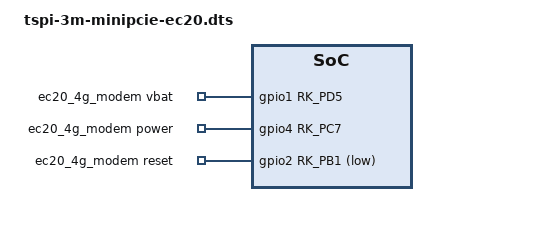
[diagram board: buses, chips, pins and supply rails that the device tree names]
/********************************************************************
 * SPDX-License-Identifier: (GPL-2.0+ OR MIT)
 *
 * Copyright (c) 2023 Rockchip Electronics Co., Ltd.
 * Copyright (c) 2026 LCKFB <lckfb@sz-jlc.com>
 *********************************************************************
 * Wiki (Chinese): https://wiki.lckfb.com/
 * Wiki (English): https://wiki.lckfb.com/en/
 *********************************************************************/

/*
 * Overlay: tspi-3m-minipcie-ec20.dtbo
 *
 * Purpose:
 *   Configures the MINI-PCIe slot for Quectel EC20 4G LTE modem.
 *   Registers the modem platform device and its GPIO pinmux.
 *   SATA0 and PCIe0 are not used in this mode and remain disabled
 *   (their default state in rk3576.dtsi).
 *
 * Hardware:
 *   - EC20 power supply (VBAT): GPIO1_D5 (active-high)
 *   - EC20 power enable:        GPIO4_C7 (active-high)
 *   - EC20 reset:               GPIO2_B1 (active-low)
 *
 * Usage:
 *   Add the following line to /boot/ubootEnv.txt and reboot:
 *     overlays=tspi-3m-minipcie-ec20.dtbo
 *
 * Mutual exclusion:
 *   Do NOT combine with tspi-3m-minipcie-pcie.dtbo or
 *   tspi-3m-minipcie-sata.dtbo. Only one MINI-PCIe overlay
 *   may be active at a time.
 *
 *   WARNING: The EC20 GPIOs (GPIO1_D5, GPIO4_C7, GPIO2_B1) are
 *   shared with the PCIe overlay. Loading both simultaneously
 *   will cause GPIO conflicts and undefined hardware behavior.
 */

/dts-v1/;
/plugin/;

#include <dt-bindings/gpio/gpio.h>
#include <dt-bindings/pinctrl/rockchip.h>

/ {
	/*-----------------------------------------------------------
	 * fragment@0 - EC20 4G Modem Pinmux
	 *
	 * Defines GPIO pinmux for all three EC20 control signals:
	 *   lte_vbat     - GPIO1_D5: VBAT power control (pull-down)
	 *   lte_power_en - GPIO4_C7: module power enable (pull-down)
	 *   lte_reset    - GPIO2_B1: module reset (pull-down)
	 *----------------------------------------------------------*/
	fragment@0 {
		target = <&pinctrl>;
		__overlay__ {
			ec20_4g_modem {
				lte_vbat: lte-vbat {
					rockchip,pins = <1 RK_PD5 RK_FUNC_GPIO &pcfg_pull_down>;
				};
				lte_power_en: lte-power-en {
					rockchip,pins = <4 RK_PC7 RK_FUNC_GPIO &pcfg_pull_down>;
				};
				lte_reset: lte-reset {
					rockchip,pins = <2 RK_PB1 RK_FUNC_GPIO &pcfg_pull_down>;
				};
			};
		};
	};

	/*-----------------------------------------------------------
	 * fragment@1 - EC20 4G Modem Platform Device
	 *
	 * Registers the EC20 modem as a platform device under the
	 * "4g-modem-platdata" driver. Binds the three GPIO signals
	 * defined in fragment@0.
	 *----------------------------------------------------------*/
	fragment@1 {
		target-path = "/";
		__overlay__ {
			ec20_4g_modem: ec20-4g-modem {
				compatible = "4g-modem-platdata";
				pinctrl-names = "default";
				pinctrl-0 = <&lte_vbat &lte_power_en &lte_reset>;
				4G,vbat-gpio  = <&gpio1 RK_PD5 GPIO_ACTIVE_HIGH>;
				4G,power-gpio = <&gpio4 RK_PC7 GPIO_ACTIVE_HIGH>;
				4G,reset-gpio = <&gpio2 RK_PB1 GPIO_ACTIVE_LOW>;
				status = "okay";
			};
		};
	};
};
